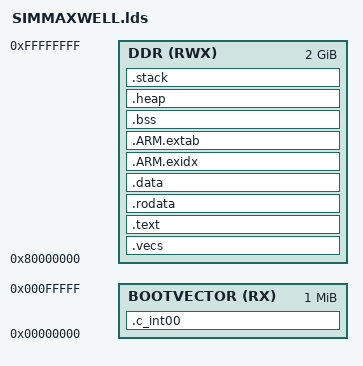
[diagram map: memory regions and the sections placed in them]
/*----------------------------------------------------------------------------*/
/* SIMMAXWELL.lds                                                             */
/*                                                                            */
/* (c) Texas Instruments 2016, All rights reserved.                           */
/*                                                                            */
/*----------------------------------------------------------------------------*/

MEMORY
{
    BOOTVECTOR (RX)  : ORIGIN =  0x00000000, LENGTH = 0x00100000
    DDR        (RWX) : ORIGIN =  0x80000000, LENGTH = 0x80000000
/*  DDR        (RWX) : ORIGIN = 0x800000000, LENGTH = 0x80000000 */
}

REGION_ALIAS("REGION_TEXT", DDR);
REGION_ALIAS("REGION_BSS", DDR);
REGION_ALIAS("REGION_DATA", DDR);
REGION_ALIAS("REGION_STACK", DDR);
REGION_ALIAS("REGION_HEAP", DDR);
REGION_ALIAS("REGION_ARM_EXIDX", DDR);
REGION_ALIAS("REGION_ARM_EXTAB", DDR);

SECTIONS {

    .c_int00 : {
        *(.c_int00)
    } > BOOTVECTOR AT> BOOTVECTOR

    .vecs : {
        *(.vecs)
    } > REGION_TEXT AT> REGION_TEXT

    .text : {
        CREATE_OBJECT_SYMBOLS
        *(.text)
        *(.text.*)
        . = ALIGN(0x4);
        KEEP (*(.ctors))
        . = ALIGN(0x4);
        KEEP (*(.dtors))
        . = ALIGN(0x4);
        __init_array_start = .;
        KEEP (*(.init_array*))
        __init_array_end = .;
        *(.init)
        *(.fini*)
    } > REGION_TEXT AT> REGION_TEXT

    PROVIDE (__etext = .);
    PROVIDE (_etext = .);
    PROVIDE (etext = .);

    .rodata : {
        *(.rodata)
        *(.rodata*)
    } > REGION_TEXT AT> REGION_TEXT

    .data : ALIGN (4) {
        __data_load__ = LOADADDR (.data);
        __data_start__ = .;
        *(.data)
        *(.data*)
        . = ALIGN (4);
        __data_end__ = .;
    } > REGION_DATA AT> REGION_TEXT

    .ARM.exidx : {
        __exidx_start = .;
        *(.ARM.exidx* .gnu.linkonce.armexidx.*)
        __exidx_end = .;
    } > REGION_ARM_EXIDX AT> REGION_ARM_EXIDX

    .ARM.extab : {
        *(.ARM.extab* .gnu.linkonce.armextab.*)
    } > REGION_ARM_EXTAB AT> REGION_ARM_EXTAB

    .bss : {
        __bss_start__ = .;
        *(.shbss)
        *(.bss)
        *(.bss.*)
        *(COMMON)
        . = ALIGN (4);
        __bss_end__ = .;
    } > REGION_BSS AT> REGION_BSS

    .heap : {
        __heap_start__ = .;
        end = __heap_start__;
        _end = end;
        __end = end;
        KEEP(*(.heap))
        __heap_end__ = .;
        __HeapLimit = __heap_end__;
    } > REGION_HEAP AT> REGION_HEAP

    .stack (NOLOAD) : ALIGN(16) {
        _stack = .;
        __stack = .;
        KEEP(*(.stack))
    } > REGION_STACK AT> REGION_STACK

    /* Stabs debugging sections.  */
    .stab          0 : { *(.stab) }
    .stabstr       0 : { *(.stabstr) }
    .stab.excl     0 : { *(.stab.excl) }
    .stab.exclstr  0 : { *(.stab.exclstr) }
    .stab.index    0 : { *(.stab.index) }
    .stab.indexstr 0 : { *(.stab.indexstr) }
    .comment       0 : { *(.comment) }
    /*
     * DWARF debug sections.
     * Symbols in the DWARF debugging sections are relative to the beginning
     * of the section so we begin them at 0.
     */
    /* DWARF 1 */
    .debug         0 : { *(.debug) }
    .line          0 : { *(.line) }
    /* GNU DWARF 1 extensions */
    .debug_srcinfo  0 : { *(.debug_srcinfo) }
    .debug_sfnames  0 : { *(.debug_sfnames) }
    /* DWARF 1.1 and DWARF 2 */
    .debug_aranges  0 : { *(.debug_aranges) }
    .debug_pubnames 0 : { *(.debug_pubnames) }
    /* DWARF 2 */
    .debug_info     0 : { *(.debug_info .gnu.linkonce.wi.*) }
    .debug_abbrev   0 : { *(.debug_abbrev) }
    .debug_line     0 : { *(.debug_line .debug_line.* .debug_line_end ) }
    .debug_frame    0 : { *(.debug_frame) }
    .debug_str      0 : { *(.debug_str) }
    .debug_loc      0 : { *(.debug_loc) }
    .debug_macinfo  0 : { *(.debug_macinfo) }
    /* SGI/MIPS DWARF 2 extensions */
    .debug_weaknames 0 : { *(.debug_weaknames) }
    .debug_funcnames 0 : { *(.debug_funcnames) }
    .debug_typenames 0 : { *(.debug_typenames) }
    .debug_varnames  0 : { *(.debug_varnames) }
    /* DWARF 3 */
    .debug_pubtypes 0 : { *(.debug_pubtypes) }
    .debug_ranges   0 : { *(.debug_ranges) }
    /* DWARF Extension.  */
    .debug_macro    0 : { *(.debug_macro) }
    .note.gnu.arm.ident 0 : { KEEP (*(.note.gnu.arm.ident)) }
    .note.gnu.build-id (NOLOAD) : { *(.note.*) }
    /DISCARD/ : { *(.note.GNU-stack) *(.gnu_debuglink) *(.gnu.lto_*) }
}

ENTRY(_c_int00)
